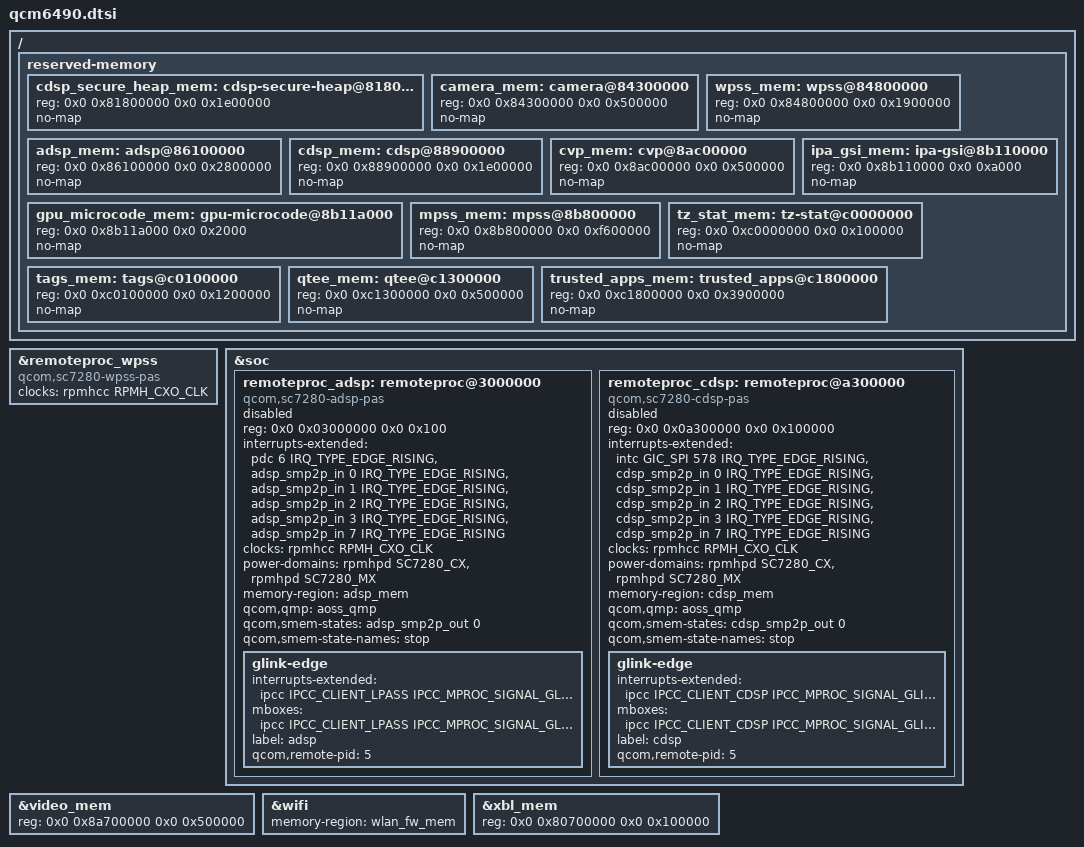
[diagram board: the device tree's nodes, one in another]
// SPDX-License-Identifier: BSD-3-Clause
/*
 * Copyright (c) 2023 Qualcomm Innovation Center, Inc. All rights reserved.
 */

#include "sc7280.dtsi"

/*
 * Delete unused sc7280 memory nodes and define the memory regions
 * required by qcm6490
 */
/delete-node/ &rmtfs_mem;
/delete-node/ &wlan_ce_mem;

/{
	reserved-memory {
		cdsp_secure_heap_mem: cdsp-secure-heap@81800000 {
			reg = <0x0 0x81800000 0x0 0x1e00000>;
			no-map;
		};

		camera_mem: camera@84300000 {
			reg = <0x0 0x84300000 0x0 0x500000>;
			no-map;
		};

		wpss_mem: wpss@84800000 {
			reg = <0x0 0x84800000 0x0 0x1900000>;
			no-map;
		};

		adsp_mem: adsp@86100000 {
			reg = <0x0 0x86100000 0x0 0x2800000>;
			no-map;
		};

		cdsp_mem: cdsp@88900000 {
			reg = <0x0 0x88900000 0x0 0x1e00000>;
			no-map;
		};

		cvp_mem: cvp@8ac00000 {
			reg = <0x0 0x8ac00000 0x0 0x500000>;
			no-map;
		};

		ipa_gsi_mem: ipa-gsi@8b110000 {
			reg = <0x0 0x8b110000 0x0 0xa000>;
			no-map;
		};

		gpu_microcode_mem: gpu-microcode@8b11a000 {
			reg = <0x0 0x8b11a000 0x0 0x2000>;
			no-map;
		};

		mpss_mem: mpss@8b800000 {
			reg = <0x0 0x8b800000 0x0 0xf600000>;
			no-map;
		};

		tz_stat_mem: tz-stat@c0000000 {
			reg = <0x0 0xc0000000 0x0 0x100000>;
			no-map;
		};

		tags_mem: tags@c0100000 {
			reg = <0x0 0xc0100000 0x0 0x1200000>;
			no-map;
		};

		qtee_mem: qtee@c1300000 {
			reg = <0x0 0xc1300000 0x0 0x500000>;
			no-map;
		};

		trusted_apps_mem: trusted_apps@c1800000 {
			reg = <0x0 0xc1800000 0x0 0x3900000>;
			no-map;
		};
	};
};

&remoteproc_wpss {
	compatible = "qcom,sc7280-wpss-pas";

	clocks = <&rpmhcc RPMH_CXO_CLK>;
	clock-names = "xo";

	/delete-property/ qcom,halt-regs;
	/delete-property/ resets;
	/delete-property/ reset-names;
};

&soc {
	remoteproc_adsp: remoteproc@3000000 {
		compatible = "qcom,sc7280-adsp-pas";
		reg = <0x0 0x03000000 0x0 0x100>;

		interrupts-extended = <&pdc 6 IRQ_TYPE_EDGE_RISING>,
					<&adsp_smp2p_in 0 IRQ_TYPE_EDGE_RISING>,
					<&adsp_smp2p_in 1 IRQ_TYPE_EDGE_RISING>,
					<&adsp_smp2p_in 2 IRQ_TYPE_EDGE_RISING>,
					<&adsp_smp2p_in 3 IRQ_TYPE_EDGE_RISING>,
					<&adsp_smp2p_in 7 IRQ_TYPE_EDGE_RISING>;
		interrupt-names = "wdog", "fatal", "ready", "handover",
				"stop-ack", "shutdown-ack";

		clocks = <&rpmhcc RPMH_CXO_CLK>;
		clock-names = "xo";

		power-domains = <&rpmhpd SC7280_CX>,
				<&rpmhpd SC7280_MX>;
		power-domain-names = "cx", "mx";

		memory-region = <&adsp_mem>;

		qcom,qmp = <&aoss_qmp>;

		qcom,smem-states = <&adsp_smp2p_out 0>;
		qcom,smem-state-names = "stop";

		status = "disabled";

		glink-edge {
			interrupts-extended = <&ipcc IPCC_CLIENT_LPASS
						IPCC_MPROC_SIGNAL_GLINK_QMP
						IRQ_TYPE_EDGE_RISING>;
			mboxes = <&ipcc IPCC_CLIENT_LPASS
					IPCC_MPROC_SIGNAL_GLINK_QMP>;
			label = "adsp";
			qcom,remote-pid = <5>;
		};
	};

	remoteproc_cdsp: remoteproc@a300000 {
		compatible = "qcom,sc7280-cdsp-pas";
		reg = <0x0 0x0a300000 0x0 0x100000>;

		interrupts-extended = <&intc GIC_SPI 578 IRQ_TYPE_EDGE_RISING>,
					<&cdsp_smp2p_in 0 IRQ_TYPE_EDGE_RISING>,
					<&cdsp_smp2p_in 1 IRQ_TYPE_EDGE_RISING>,
					<&cdsp_smp2p_in 2 IRQ_TYPE_EDGE_RISING>,
					<&cdsp_smp2p_in 3 IRQ_TYPE_EDGE_RISING>,
					<&cdsp_smp2p_in 7 IRQ_TYPE_EDGE_RISING>;
		interrupt-names = "wdog", "fatal", "ready", "handover",
				"stop-ack", "shutdown-ack";

		clocks = <&rpmhcc RPMH_CXO_CLK>;
		clock-names = "xo";

		power-domains = <&rpmhpd SC7280_CX>,
				<&rpmhpd SC7280_MX>;
		power-domain-names = "cx", "mx";

		memory-region = <&cdsp_mem>;

		qcom,qmp = <&aoss_qmp>;

		qcom,smem-states = <&cdsp_smp2p_out 0>;
		qcom,smem-state-names = "stop";

		status = "disabled";

		glink-edge {
			interrupts-extended = <&ipcc IPCC_CLIENT_CDSP
						IPCC_MPROC_SIGNAL_GLINK_QMP
						IRQ_TYPE_EDGE_RISING>;
			mboxes = <&ipcc IPCC_CLIENT_CDSP
					IPCC_MPROC_SIGNAL_GLINK_QMP>;
			label = "cdsp";
			qcom,remote-pid = <5>;
		};
	};
};

&video_mem {
	reg = <0x0 0x8a700000 0x0 0x500000>;
};

&wifi {
	memory-region = <&wlan_fw_mem>;
};

&xbl_mem {
	reg = <0x0 0x80700000 0x0 0x100000>;
};
